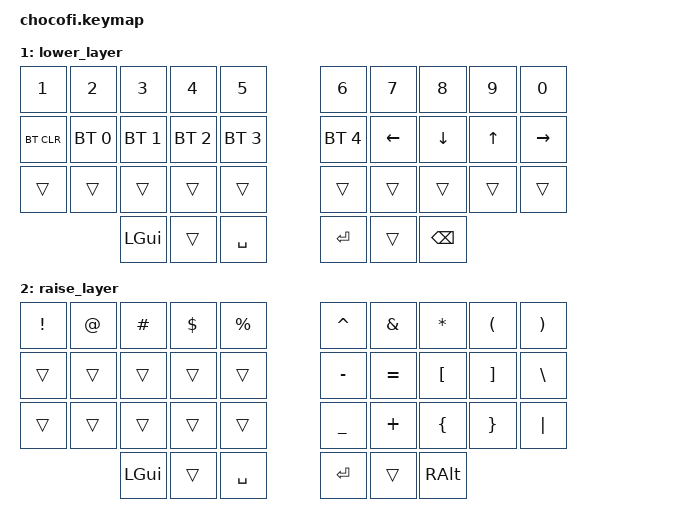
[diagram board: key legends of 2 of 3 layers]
/*
 * Copyright (c) 2020 The ZMK Contributors
 *
 * SPDX-License-Identifier: MIT
 */

#include <behaviors.dtsi>
#include <dt-bindings/zmk/keys.h>
#include <dt-bindings/zmk/bt.h>

/ {
        keymap {
                compatible = "zmk,keymap";

                default_layer {
                        bindings = <
        
// ----------------------------------------------------------------------------------------
   &kp Q  &kp W   &kp F &kp P &kp G   &kp J &kp L  &kp U s     &kp Y   &kp SEMI  
// -----------------------------------------------------------------------------------------
   &kp A  &kp R   &kp S &kp T &kp D   &kp H &kp N  &kp E     &kp I   &kp O
// -----------------------------------------------------------------------------------------
   &kp Z  &kp X   &kp C &kp V &kp B   &kp K &kp M  &kp COMMA &kp DOT &kp FSLH
// -----------------------------------------------------------------------------------------
          &kp LGUI &mo 1  &kp SPACE   &kp RET   &mo 2   &kp RALT


                        >;
                };

                lower_layer {
// -----------------------------------------------------------------------------------------
// |  1   |  2  |  3  |  4   |  5 |   |  6  |  7  |  8  |  9  |  0 |
// |  BT1 | BT2 | BT3 | BT4 | BT5 |   | LFT | DWN |  UP | RGT |    |
// |      |     |     |     |     |   |     |     |     |     |    |
//               | GUI |    | SPC |   | ENT |     | ALT |
                        bindings = <
    
// -----------------------------------------------------------------------------------------
   &kp N1     &kp N2       &kp N3       &kp N4       &kp N5       &kp N6       &kp N7   &kp N8   &kp N9 &kp N0
// -----------------------------------------------------------------------------------------
   &bt BT_CLR &bt BT_SEL 0 &bt BT_SEL 1 &bt BT_SEL 2 &bt BT_SEL 3 &bt BT_SEL 4 &kp LEFT &kp DOWN &kp UP &kp RIGHT
// -----------------------------------------------------------------------------------------
   &trans     &trans       &trans       &trans       &trans       &trans       &trans   &trans   &trans &trans   
// -----------------------------------------------------------------------------------------
        &kp LGUI  &trans &kp SPACE &kp RET  &trans   &kp BSPC
                        >;
                };

                raise_layer {
// -----------------------------------------------------------------------------------------
// |  !  |  @  |  #  |  $  |  %  |   |  ^  |  &  |  *  |  (  |  )  |
// |     |     |     |     |     |   |  -  |  =  |  [  |  ]  |  \  |
// |     |     |     |     |     |   |  _  |  +  |  {  |  }  | "|" |
//             | GUI |     | SPC |   | ENT |     | ALT |
                        bindings = <
// -----------------------------------------------------------------------------------------
   &kp EXCL &kp AT   &kp HASH &kp DLLR  &kp PRCNT      &kp CARET &kp AMPS  &kp ASTRK &kp LPAR &kp RPAR
// -----------------------------------------------------------------------------------------
   &trans   &trans   &trans   &trans    &trans         &kp MINUS &kp EQUAL &kp LBKT  &kp RBKT &kp BSLH
// -----------------------------------------------------------------------------------------
   &trans   &trans   &trans   &trans    &trans         &kp UNDER &kp PLUS  &kp LBRC  &kp RBRC &kp PIPE
// -----------------------------------------------------------------------------------------
                     &kp LGUI &trans   &kp SPACE      &kp RET   &trans    &kp RALT
                        >;
                };
        };
};
